# STM32G07x register map
File version: 1.3
CPU: CM0+ r0p0, little endian, no MPU, no FPU, 3 interrupt priority bits
Registers are 32-bit, read-write, reset 0x0 unless marked. A register's access mark holds for its fields unless they carry their own. Offsets are from the block's base; [hi:lo] are bit positions.

## DAC
Base 0x40007400
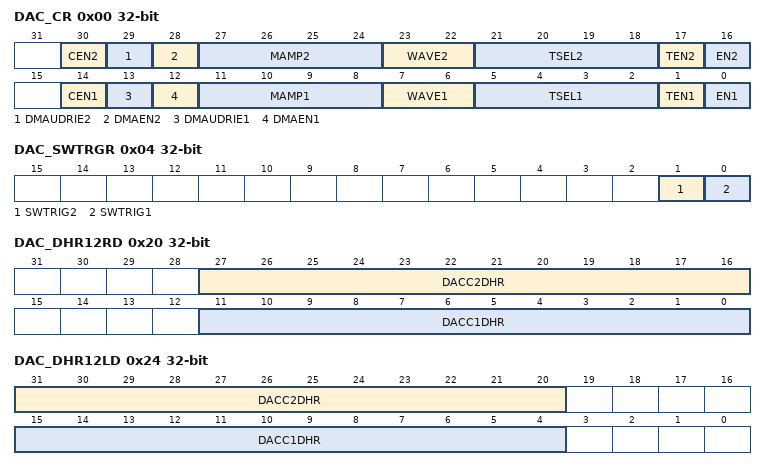
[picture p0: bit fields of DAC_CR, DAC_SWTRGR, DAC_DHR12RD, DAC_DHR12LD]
0x00 DAC_CR — DAC control register
  [30] CEN2 — DAC Channel 2 calibration enable This bit is set and cleared by software to enable/disable DAC channel 2 calibration, it can be written only if bit EN2=0 into DAC_CR (the calibration mode can be entered/exit only when the DAC channel is disabled) Otherwise, the write operation is ignored.
  [29] DMAUDRIE2 — DAC channel2 DMA underrun interrupt enable This bit is set and cleared by software.
  [28] DMAEN2 — DAC channel2 DMA enable This bit is set and cleared by software.
  [27:24] MAMP2 — DAC channel2 mask/amplitude selector These bits are written by software to select mask in wave generation mode or amplitude in triangle generation mode. = 1011: Unmask bits[11:0] of LFSR/ triangle amplitude equal to 4095
  [23:22] WAVE2 — DAC channel2 noise/triangle wave generation enable These bits are set/reset by software. 1x: Triangle wave generation enabled Note: Only used if bit TEN2 = 1 (DAC channel2 trigger enabled)
  [21:18] TSEL2 — DAC channel2 trigger selection These bits select the external event used to trigger DAC channel2 Note: Only used if bit TEN2 = 1 (DAC channel2 trigger enabled).
  [17] TEN2 — DAC channel2 trigger enable
  [16] EN2 — DAC channel2 enable This bit is set and cleared by software to enable/disable DAC channel2.
  [14] CEN1 — DAC Channel 1 calibration enable This bit is set and cleared by software to enable/disable DAC channel 1 calibration, it can be written only if bit EN1=0 into DAC_CR (the calibration mode can be entered/exit only when the DAC channel is disabled) Otherwise, the write operation is ignored.
  [13] DMAUDRIE1 — DAC channel1 DMA Underrun Interrupt enable This bit is set and cleared by software.
  [12] DMAEN1 — DAC channel1 DMA enable This bit is set and cleared by software.
  [11:8] MAMP1 — DAC channel1 mask/amplitude selector These bits are written by software to select mask in wave generation mode or amplitude in triangle generation mode. = 1011: Unmask bits[11:0] of LFSR/ triangle amplitude equal to 4095
  [7:6] WAVE1 — DAC channel1 noise/triangle wave generation enable These bits are set and cleared by software. Note: Only used if bit TEN1 = 1 (DAC channel1 trigger enabled).
  [5:2] TSEL1 — DAC channel1 trigger selection These bits select the external event used to trigger DAC channel1. Note: Only used if bit TEN1 = 1 (DAC channel1 trigger enabled).
  [1] TEN1 — DAC channel1 trigger enable
  [0] EN1 — DAC channel1 enable This bit is set and cleared by software to enable/disable DAC channel1.
0x04 DAC_SWTRGR wo — DAC software trigger register
  [1] SWTRIG2 — DAC channel2 software trigger This bit is set by software to trigger the DAC in software trigger mode. Note: This bit is cleared by hardware (one APB1 clock cycle later) once the DAC_DHR2 register value has been loaded into the DAC_DOR2 register.
  [0] SWTRIG1 — DAC channel1 software trigger This bit is set by software to trigger the DAC in software trigger mode. Note: This bit is cleared by hardware (one APB1 clock cycle later) once the DAC_DHR1 register value has been loaded into the DAC_DOR1 register.
0x08 DAC_DHR12R1 — DAC channel1 12-bit right-aligned data holding register
  [11:0] DACC1DHR — DAC channel1 12-bit right-aligned data These bits are written by software which specifies 12-bit data for DAC channel1.
0x0C DAC_DHR12L1 — DAC channel1 12-bit left aligned data holding register
  [15:4] DACC1DHR — DAC channel1 12-bit left-aligned data These bits are written by software which specifies 12-bit data for DAC channel1.
0x10 DAC_DHR8R1 — DAC channel1 8-bit right aligned data holding register
  [7:0] DACC1DHR — DAC channel1 8-bit right-aligned data These bits are written by software which specifies 8-bit data for DAC channel1.
0x14 DAC_DHR12R2 — DAC channel2 12-bit right aligned data holding register
  [11:0] DACC2DHR — DAC channel2 12-bit right-aligned data These bits are written by software which specifies 12-bit data for DAC channel2.
0x18 DAC_DHR12L2 — DAC channel2 12-bit left aligned data holding register
  [15:4] DACC2DHR — DAC channel2 12-bit left-aligned data These bits are written by software which specify 12-bit data for DAC channel2.
0x1C DAC_DHR8R2 — DAC channel2 8-bit right-aligned data holding register
  [7:0] DACC2DHR — DAC channel2 8-bit right-aligned data These bits are written by software which specifies 8-bit data for DAC channel2.
0x20 DAC_DHR12RD — Dual DAC 12-bit right-aligned data holding register
  [27:16] DACC2DHR — DAC channel2 12-bit right-aligned data These bits are written by software which specifies 12-bit data for DAC channel2.
  [11:0] DACC1DHR — DAC channel1 12-bit right-aligned data These bits are written by software which specifies 12-bit data for DAC channel1.
0x24 DAC_DHR12LD — DUAL DAC 12-bit left aligned data holding register
  [31:20] DACC2DHR — DAC channel2 12-bit left-aligned data These bits are written by software which specifies 12-bit data for DAC channel2.
  [15:4] DACC1DHR — DAC channel1 12-bit left-aligned data These bits are written by software which specifies 12-bit data for DAC channel1.
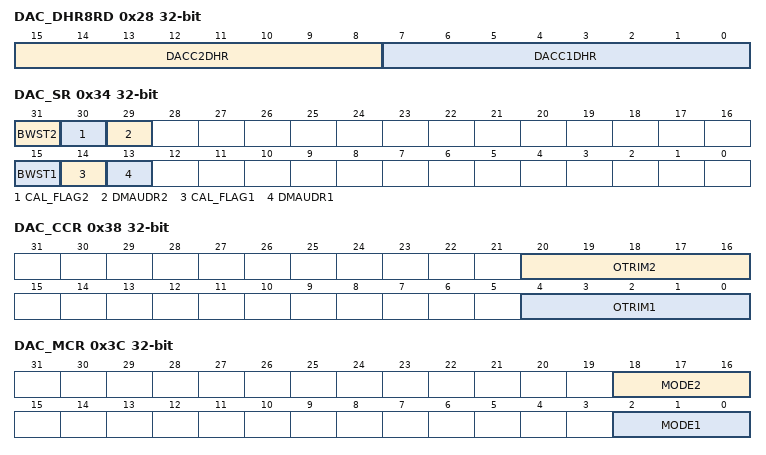
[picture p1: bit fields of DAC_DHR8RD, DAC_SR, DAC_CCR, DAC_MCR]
0x28 DAC_DHR8RD — DUAL DAC 8-bit right aligned data holding register
  [15:8] DACC2DHR — DAC channel2 8-bit right-aligned data These bits are written by software which specifies 8-bit data for DAC channel2.
  [7:0] DACC1DHR — DAC channel1 8-bit right-aligned data These bits are written by software which specifies 8-bit data for DAC channel1.
0x2C DAC_DOR1 ro — DAC channel1 data output register
  [11:0] DACC1DOR — DAC channel1 data output These bits are read-only, they contain data output for DAC channel1.
0x30 DAC_DOR2 ro — DAC channel2 data output register
  [11:0] DACC2DOR — DAC channel2 data output These bits are read-only, they contain data output for DAC channel2.
0x34 DAC_SR access per field — DAC status register
  [31] BWST2 ro — DAC Channel 2 busy writing sample time flag This bit is systematically set just after Sample & Hold mode enable and is set each time the software writes the register DAC_SHSR2, It is cleared by hardware when the write operation of DAC_SHSR2 is complete. (It takes about 3 LSI periods of synchronization).
  [30] CAL_FLAG2 ro — DAC Channel 2 calibration offset status This bit is set and cleared by hardware
  [29] DMAUDR2 rw — DAC channel2 DMA underrun flag This bit is set by hardware and cleared by software (by writing it to 1).
  [15] BWST1 ro — DAC Channel 1 busy writing sample time flag This bit is systematically set just after Sample & Hold mode enable and is set each time the software writes the register DAC_SHSR1, It is cleared by hardware when the write operation of DAC_SHSR1 is complete. (It takes about 3LSI periods of synchronization).
  [14] CAL_FLAG1 ro — DAC Channel 1 calibration offset status This bit is set and cleared by hardware
  [13] DMAUDR1 rw — DAC channel1 DMA underrun flag This bit is set by hardware and cleared by software (by writing it to 1).
0x38 DAC_CCR — DAC calibration control register
  [20:16] OTRIM2 — DAC Channel 2 offset trimming value
  [4:0] OTRIM1 — DAC Channel 1 offset trimming value
0x3C DAC_MCR — DAC mode control register
  [18:16] MODE2 — DAC Channel 2 mode These bits can be written only when the DAC is disabled and not in the calibration mode (when bit EN2=0 and bit CEN2 =0 in the DAC_CR register). If EN2=1 or CEN2 =1 the write operation is ignored. They can be set and cleared by software to select the DAC Channel 2 mode: DAC Channel 2 in normal Mode DAC Channel 2 in sample & hold mode
  [2:0] MODE1 — DAC Channel 1 mode These bits can be written only when the DAC is disabled and not in the calibration mode (when bit EN1=0 and bit CEN1 =0 in the DAC_CR register). If EN1=1 or CEN1 =1 the write operation is ignored. They can be set and cleared by software to select the DAC Channel 1 mode: DAC Channel 1 in normal Mode DAC Channel 1 in sample & hold mode
0x40 DAC_SHSR1 — DAC Sample and Hold sample time register 1
  [9:0] TSAMPLE1 — DAC Channel 1 sample Time (only valid in sample & hold mode) These bits can be written when the DAC channel1 is disabled or also during normal operation. in the latter case, the write can be done only when BWSTx of DAC_SR register is low, If BWSTx=1, the write operation is ignored.
0x44 DAC_SHSR2 — DAC Sample and Hold sample time register 2
  [9:0] TSAMPLE2 — DAC Channel 2 sample Time (only valid in sample & hold mode) These bits can be written when the DAC channel2 is disabled or also during normal operation. in the latter case, the write can be done only when BWSTx of DAC_SR register is low, if BWSTx=1, the write operation is ignored.
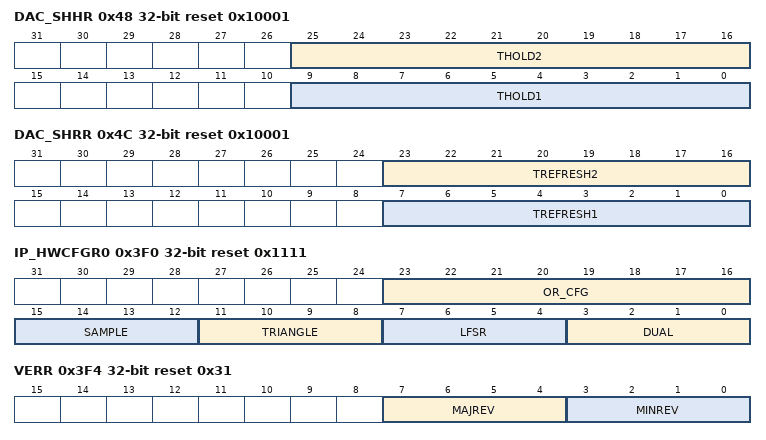
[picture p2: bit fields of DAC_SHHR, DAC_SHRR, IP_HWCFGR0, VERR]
0x48 DAC_SHHR reset 0x10001 — DAC Sample and Hold hold time register
  [25:16] THOLD2 — DAC Channel 2 hold time (only valid in sample & hold mode). Hold time= (THOLD[9:0]) x T LSI
  [9:0] THOLD1 — DAC Channel 1 hold Time (only valid in sample & hold mode) Hold time= (THOLD[9:0]) x T LSI
0x4C DAC_SHRR reset 0x10001 — DAC Sample and Hold refresh time register
  [23:16] TREFRESH2 — DAC Channel 2 refresh Time (only valid in sample & hold mode) Refresh time= (TREFRESH[7:0]) x T LSI
  [7:0] TREFRESH1 — DAC Channel 1 refresh Time (only valid in sample & hold mode) Refresh time= (TREFRESH[7:0]) x T LSI
0x3F0 IP_HWCFGR0 reset 0x1111 — DAC IP Hardware Configuration Register
  [23:16] OR_CFG — option register bit width
  [15:12] SAMPLE — Sample and hold mode capability
  [11:8] TRIANGLE — Triangle wave generation capability
  [7:4] LFSR — Pseudonoise wave generation capability
  [3:0] DUAL — Dual DAC capability
0x3F4 VERR ro reset 0x31 — EXTI IP Version register
  [7:4] MAJREV — Major Revision number
  [3:0] MINREV — Minor Revision number
0x3F8 IPIDR ro reset 0x110011 — EXTI Identification register
  [31:0] IPID — IP Identification
0x3FC SIDR ro reset 0xA3C5DD01 — EXTI Size ID register
  [31:0] SID — Size Identification
